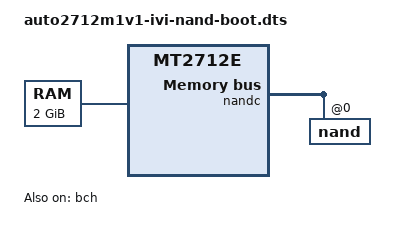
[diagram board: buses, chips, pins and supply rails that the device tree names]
/*
 * Copyright (c) 2017 MediaTek Inc.
 * Author: Eddie Huang <eddie.huang@mediatek.com>
 *
 * This program is free software; you can redistribute it and/or modify
 * it under the terms of the GNU General Public License version 2 as
 * published by the Free Software Foundation.
 *
 * This program is distributed in the hope that it will be useful,
 * but WITHOUT ANY WARRANTY; without even the implied warranty of
 * MERCHANTABILITY or FITNESS FOR A PARTICULAR PURPOSE.  See the
 * GNU General Public License for more details.
 */

/dts-v1/;
#include "mt2712e.dtsi"
#include "auto2712m1v1-common.dtsi"

/ {
	chosen {
		bootargs = "console=ttyS0,921600n1 ubi.mtd=5 rootfstype=ubifs \
root=ubi0:auto2712m1v1-ivi_agl-nand-rootfs ubi.mtd=6 debugshell=1 printk.disable_uart=0 \
rootwait initcall_debug=1 loglevel=8 earlycon=uart8250,mmio32,0x11002000";
	};

	memory@40000000 {
		device_type = "memory";
		reg = <0 0x40000000 0 0x80000000>;
	};
};

&bch {
	status = "okay";
};

&nandc {
	pinctrl-names = "default";
	pinctrl-0 = <&nand_pins_default>;
	status = "okay";
	nand@0 {
		reg = <0>;
		nand-on-flash-bbt;
		nand-ecc-mode = "hw";
	};
};
